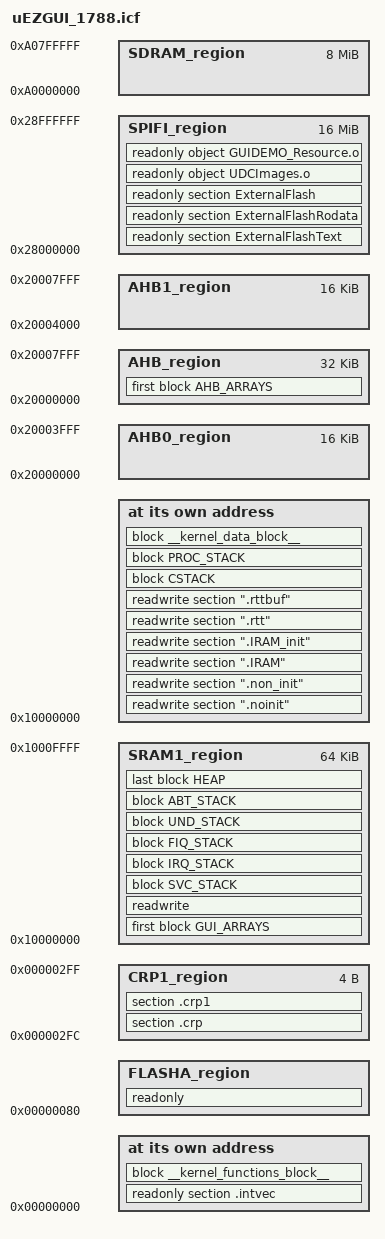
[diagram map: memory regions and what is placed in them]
/*###ICF### Section handled by ICF editor, don't touch! ****/
/*-Editor annotation file-*/
/* IcfEditorFile="$TOOLKIT_DIR$\config\ide\IcfEditor\cortex_v1_0.xml" */
/*-Specials-*/
define symbol __ICFEDIT_intvec_start__ = 0x00000000;
/*-Memory Regions-*/
/*-Sizes-*/
define symbol __ICFEDIT_size_heap__        = 40960;
define symbol __ICFEDIT_size_cstack__      = 0x400;  // main stack
define symbol __ICFEDIT_size_proc_stack__  = 0x0;    // process stack for MPU RTOS port usage
define symbol __ICFEDIT_size_svcstack__    = 0x10;   // These stacks aren't normally used in uEZGUI/Cortex-M projects.
define symbol __ICFEDIT_size_irqstack__    = 0x100;
define symbol __ICFEDIT_size_fiqstack__    = 0x100;
define symbol __ICFEDIT_size_undstack__    = 0x10;
define symbol __ICFEDIT_size_abtstack__    = 0x10;
/**** End of ICF editor section. ###ICF###*/

/*-- Sizes: -----------------------------------------------------------------*/
/* This must match the number of implemented vectors * 4 and be padded to an 8 byte boundary
(check the mapfile to ensure that the kernel function region is correctly occupying
the first 8K region of flash). There does not seem to be any way of dynamically
determining the size of the vector table section at link time, hence this direct definition. */
define symbol __size_vectors__              = 0xE8;
define memory mem with size = 4G;

/*-- uEZ Defines: -----------------------------------------------------------*/
/*-Memory Region Start and End Addresss symbols-*/
/********** Flash Bank A Region **********/
define symbol FLASHA_start__     = 0x00000080;
define symbol FLASHA_end__       = 0x0007FFFF;
/********* CRP (Code Read Protection) Region *********/
define symbol CRP1_start__       = 0x000002FC;
define symbol CRP1_end__         = 0x000002FF;
/********* Internal RAM Regions *********/
define symbol SRAM1_start        = 0x10000000;
define symbol SRAM1_end          = 0x1000FFFF;
define symbol AHB0_start         = 0x20000000;
define symbol AHB0_end           = 0x20003FFF;
define symbol AHB1_start         = 0x20004000;
define symbol AHB1_end           = 0x20007FFF;
/********* External RAM and Flash Regions *********/
define symbol SDRAM_start__      = 0xA0000000;
define symbol SDRAM_end__        = 0xA07FFFFF; // Increase this for 16MB SDRAM units
define symbol SPIFI_start        = 0x28000000;
define symbol SPIFI_end          = 0x28FFFFFF;

/*-- Memory Regions defines: ----------------------------------------------------*/
define region FLASHA_region = mem:[from FLASHA_start__ to FLASHA_end__] - mem:[from CRP1_start__ to CRP1_end__];
define region CRP1_region = mem:[from  CRP1_start__ to CRP1_end__];
define region SRAM1_region = mem:[from SRAM1_start to SRAM1_end];
define region AHB0_region = mem:[from AHB0_start to AHB0_end];
define region AHB1_region = mem:[from AHB1_start to AHB1_end];
define region AHB_region = mem:[from AHB0_start to AHB1_end];
define region SDRAM_region = mem:[from SDRAM_start__ to SDRAM_end__];
define region SPIFI_region = mem:[from SPIFI_start to SPIFI_end];
/*-- Blocks: ----------------------------------------------------------------*/
define block HEAP       with alignment = 8, minimum size = __ICFEDIT_size_heap__, expanding size { rw section ".heap" };
define block CSTACK     with alignment = 8, size = __ICFEDIT_size_cstack__   { };
define block PROC_STACK with alignment = 8, size = __ICFEDIT_size_proc_stack__ { };
define block SVC_STACK  with alignment = 8, size = __ICFEDIT_size_svcstack__ { };
define block IRQ_STACK  with alignment = 8, size = __ICFEDIT_size_irqstack__ { };
define block FIQ_STACK  with alignment = 8, size = __ICFEDIT_size_fiqstack__ { };
define block UND_STACK  with alignment = 8, size = __ICFEDIT_size_undstack__ { };
define block ABT_STACK  with alignment = 8, size = __ICFEDIT_size_abtstack__ { };

/*-- Placment Commands (General): -------------------------------------------*/
initialize by copy { readwrite };
do not initialize  { section .noinit, section .non_init };

/* Define a block for the kernel's functions.  - __size_vectors__ because the 
first part of the 8K is taken by the interrupt vectors. */
define block __kernel_functions_block__ with alignment = 8, 
    size = 0x2000 - __size_vectors__ { section __kernel_functions__ };

/* Place the interrupt vectors at the required address, followed by the kernel's functions. */
place at address mem:__ICFEDIT_intvec_start__ { 
    readonly section .intvec, 
    block __kernel_functions_block__ 
};
/* Define a block for the kernel's data. */
define block __kernel_data_block__ with alignment = 0x400, size = 0x400 { section __kernel_data__ };

place in FLASHA_region   { readonly };
/* Place the main stack at the start of IRAM, followed by the kernel's data. */
/* Use the Internal SRAM for the system stack and the kernel data. */
place at address mem:SRAM1_start {
    readwrite section ".noinit",
    readwrite section ".non_init",
    readwrite section ".IRAM", //PLL, SDRAM, IAP
    readwrite section ".IRAM_init", //PLL, SDRAM, IAP
    readwrite section ".rtt", /*SEGGER_RTT_SECTION*/
    readwrite section ".rttbuf", /*SEGGER_RTT_BUFFER_SECTION*/
    block CSTACK,
	block PROC_STACK,
    block __kernel_data_block__, 
    //rw object LPC17xx_40xx_PLL.o
};
/* Place these sections in order at the very beginning of SDRAM */
define block GUI_ARRAYS with fixed order {
    readwrite section ".frames", /*Frames section*/
    readwrite section ".video",
    readwrite section ".emWin", /*emWin section*/
    /*Move rttbuf section here when using systemview with large trace buffer allocation. May break some RAM tests. */
    readwrite section ".network" /*Network section*/
};

place in SRAM1_region { 
    first block GUI_ARRAYS,
    readwrite,
    block SVC_STACK, 
    block IRQ_STACK, 
    block FIQ_STACK,
    block UND_STACK, 
    block ABT_STACK, 
    last block HEAP // by default expand to fill remaining SDRAM
};

place in SDRAM_region { 
};

place in SPIFI_region { 
    readonly section ExternalFlashText,
    readonly section ExternalFlashRodata,
    readonly section ExternalFlash,
    readonly object UDCImages.o,
    readonly object GUIDEMO_Resource.o
};
define block AHB_ARRAYS with fixed order {
    readwrite section .usbhostmem,
    readwrite section .mcimem,
    readwrite section .emacmem,
};
place in AHB_region {
    first block AHB_ARRAYS,
};
place in AHB0_region {};
place in AHB1_region {};

place in CRP1_region { section .crp,  section .crp1 };
/*-- Exports: ---------------------------------------------------------------*/
/* Export symbols required by c code. */
export symbol __ICFEDIT_intvec_start__;
export symbol __ICFEDIT_size_cstack__;
export symbol FLASHA_start__;
export symbol FLASHA_end__;
export symbol SRAM1_end;
export symbol SDRAM_end__;
